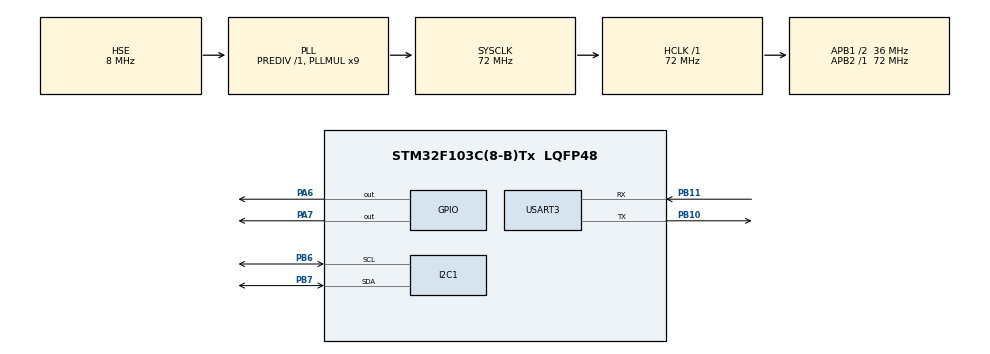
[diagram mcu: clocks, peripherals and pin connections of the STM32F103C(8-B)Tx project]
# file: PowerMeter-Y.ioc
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Dma.Request0=USART3_TX
Dma.Request1=USART3_RX
Dma.USART3_RX.1.Direction=DMA_PERIPH_TO_MEMORY
Dma.USART3_RX.1.Instance=DMA1_Channel3
Dma.USART3_RX.1.MemDataAlignment=DMA_MDATAALIGN_BYTE
Dma.USART3_RX.1.MemInc=DMA_MINC_ENABLE
Dma.USART3_RX.1.Mode=DMA_CIRCULAR
Dma.USART3_RX.1.PeriphDataAlignment=DMA_PDATAALIGN_BYTE
Dma.USART3_RX.1.PeriphInc=DMA_PINC_DISABLE
Dma.USART3_RX.1.Priority=DMA_PRIORITY_LOW
Dma.USART3_TX.0.Direction=DMA_MEMORY_TO_PERIPH
Dma.USART3_TX.0.Instance=DMA1_Channel2
Dma.USART3_TX.0.MemDataAlignment=DMA_MDATAALIGN_BYTE
Dma.USART3_TX.0.MemInc=DMA_MINC_ENABLE
Dma.USART3_TX.0.Mode=DMA_CIRCULAR
Dma.USART3_TX.0.PeriphDataAlignment=DMA_PDATAALIGN_BYTE
Dma.USART3_TX.0.PeriphInc=DMA_PINC_DISABLE
Dma.USART3_TX.0.Priority=DMA_PRIORITY_LOW
FREERTOS.Tasks01=Communicate,0,128,CommunicateTask,As weak,NULL,Dynamic,NULL,NULL
Mcu.Family=STM32F1
Mcu.Name=STM32F103C(8-B)Tx
Mcu.Package=LQFP48
NVIC.DMA1_Channel2_IRQn=true\:5\:0\:false\:false\:true\:true\:false\:true\:true
NVIC.DMA1_Channel3_IRQn=true\:5\:0\:false\:false\:true\:true\:false\:true\:true
NVIC.PriorityGroup=NVIC_PRIORITYGROUP_4
NVIC.TIM4_IRQn=true\:15\:0\:false\:false\:true\:false\:false\:true\:true
NVIC.TimeBase=TIM4_IRQn
NVIC.TimeBaseIP=TIM4
NVIC.USART3_IRQn=true\:5\:0\:false\:false\:true\:true\:true\:true\:true
PA13.Mode=Serial_Wire
PA13.Signal=SYS_JTMS-SWDIO
PA14.Mode=Serial_Wire
PA14.Signal=SYS_JTCK-SWCLK
PA6.GPIO_Speed=GPIO_SPEED_FREQ_HIGH
PA6.Signal=GPIO_Output
PA7.GPIO_Speed=GPIO_SPEED_FREQ_HIGH
PA7.Signal=GPIO_Output
PB10.Mode=Asynchronous
PB10.Signal=USART3_TX
PB11.Mode=Asynchronous
PB11.Signal=USART3_RX
PB6.Mode=I2C
PB6.Signal=I2C1_SCL
PB7.Mode=I2C
PB7.Signal=I2C1_SDA
PD0-OSC_IN.Mode=HSE-External-Oscillator
PD0-OSC_IN.Signal=RCC_OSC_IN
PD1-OSC_OUT.Mode=HSE-External-Oscillator
PD1-OSC_OUT.Signal=RCC_OSC_OUT
ProjectManager.HeapSize=0x200
ProjectManager.StackSize=0x400
ProjectManager.TargetToolchain=CMake
RCC.AHBFreq_Value=72000000
RCC.APB1CLKDivider=RCC_HCLK_DIV2
RCC.APB1Freq_Value=36000000
RCC.APB1TimFreq_Value=72000000
RCC.APB2Freq_Value=72000000
RCC.APB2TimFreq_Value=72000000
RCC.HCLKFreq_Value=72000000
RCC.PLLMUL=RCC_PLL_MUL9
RCC.PLLSourceVirtual=RCC_PLLSOURCE_HSE
RCC.SYSCLKFreq_VALUE=72000000
RCC.SYSCLKSource=RCC_SYSCLKSOURCE_PLLCLK
RCC.USBFreq_Value=72000000
USART3.VirtualMode=VM_ASYNC
VP_FREERTOS_VS_CMSIS_V1.Mode=CMSIS_V1
VP_SYS_VS_tim4.Mode=TIM4
board=custom

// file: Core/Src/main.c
/* USER CODE BEGIN Header */
/**
  ******************************************************************************
  * @file           : main.c
  * @brief          : Main program body
  ******************************************************************************
  * @attention
  *
  * Copyright (c) 2026 STMicroelectronics.
  * All rights reserved.
  *
  * This software is licensed under terms that can be found in the LICENSE file
  * in the root directory of this software component.
  * If no LICENSE file comes with this software, it is provided AS-IS.
  *
  ******************************************************************************
  */
/* USER CODE END Header */
#include "main.h"
#include "cmsis_os.h"
#include "dma.h"
#include "i2c.h"
#include "usart.h"
#include "gpio.h"

/* USER CODE BEGIN Includes */
#include "../../UserLib/INA226/INA226.h"
/* USER CODE END Includes */

/* USER CODE BEGIN PM */
uint8_t dma_flag = 1;
/* USER CODE END PM */

void SystemClock_Config(void);
void MX_FREERTOS_Init(void);

int main(void)
{

  /* MCU Configuration--------------------------------------------------------*/

  /* Reset of all peripherals, Initializes the Flash interface and the Systick. */
  HAL_Init();

  /* Configure the system clock */
  SystemClock_Config();

  /* Initialize all configured peripherals */
  MX_GPIO_Init();
  MX_DMA_Init();
  MX_I2C1_Init();
  MX_USART3_UART_Init();
  /* USER CODE BEGIN 2 */
  static float busvoltage;
  static float current;
  static float power;
  /* USER CODE END 2 */

  /* Call init function for freertos objects (in cmsis_os2.c) */
  MX_FREERTOS_Init();

  /* Start scheduler */
  osKernelStart();

  /* We should never get here as control is now taken by the scheduler */

  /* Infinite loop */
  /* USER CODE BEGIN WHILE */
  while (1)
  {
    if (Check() == 0) {
    busvoltage = BusVoltage();
      current = Current();
      power = Power();
    }
    HAL_Delay(50);
    /* USER CODE END WHILE */

  }
}

void SystemClock_Config(void)
{
  RCC_OscInitTypeDef RCC_OscInitStruct = {0};
  RCC_ClkInitTypeDef RCC_ClkInitStruct = {0};

  /** Initializes the RCC Oscillators according to the specified parameters
  * in the RCC_OscInitTypeDef structure.
  */
  RCC_OscInitStruct.OscillatorType = RCC_OSCILLATORTYPE_HSE;
  RCC_OscInitStruct.HSEState = RCC_HSE_ON;
  RCC_OscInitStruct.HSEPredivValue = RCC_HSE_PREDIV_DIV1;
  RCC_OscInitStruct.HSIState = RCC_HSI_ON;
  RCC_OscInitStruct.PLL.PLLState = RCC_PLL_ON;
  RCC_OscInitStruct.PLL.PLLSource = RCC_PLLSOURCE_HSE;
  RCC_OscInitStruct.PLL.PLLMUL = RCC_PLL_MUL9;
  if (HAL_RCC_OscConfig(&RCC_OscInitStruct) != HAL_OK)
  {
    Error_Handler();
  }

  /** Initializes the CPU, AHB and APB buses clocks
  */
  RCC_ClkInitStruct.ClockType = RCC_CLOCKTYPE_HCLK|RCC_CLOCKTYPE_SYSCLK
                              |RCC_CLOCKTYPE_PCLK1|RCC_CLOCKTYPE_PCLK2;
  RCC_ClkInitStruct.SYSCLKSource = RCC_SYSCLKSOURCE_PLLCLK;
  RCC_ClkInitStruct.AHBCLKDivider = RCC_SYSCLK_DIV1;
  RCC_ClkInitStruct.APB1CLKDivider = RCC_HCLK_DIV2;
  RCC_ClkInitStruct.APB2CLKDivider = RCC_HCLK_DIV1;

  if (HAL_RCC_ClockConfig(&RCC_ClkInitStruct, FLASH_LATENCY_2) != HAL_OK)
  {
    Error_Handler();
  }
}

void HAL_TIM_PeriodElapsedCallback(TIM_HandleTypeDef *htim)
{
  if (htim->Instance == TIM4)
  {
    HAL_IncTick();
  }
}

void Error_Handler(void)
{
  /* USER CODE BEGIN Error_Handler_Debug */
  /* UserLib can add his own implementation to report the HAL error return state */
  __disable_irq();
  while (1)
  {
  }
  /* USER CODE END Error_Handler_Debug */
}

#ifdef  USE_FULL_ASSERT
/**
  * @brief  Reports the name of the source file and the source line number
  *         where the assert_param error has occurred.
  * @param  file: pointer to the source file name
  * @param  line: assert_param error line source number
  * @retval None
  */
void assert_failed(uint8_t *file, uint32_t line)
{
  /* USER CODE BEGIN 6 */
  /* UserLib can add his own implementation to report the file name and line number,
     ex: printf("Wrong parameters value: file %s on line %d\r\n", file, line) */
  /* USER CODE END 6 */
}
#endif /* USE_FULL_ASSERT */

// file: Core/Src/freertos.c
/* USER CODE BEGIN Header */
/**
  ******************************************************************************
  * File Name          : freertos.c
  * Description        : Code for freertos applications
  ******************************************************************************
  * @attention
  *
  * Copyright (c) 2026 STMicroelectronics.
  * All rights reserved.
  *
  * This software is licensed under terms that can be found in the LICENSE file
  * in the root directory of this software component.
  * If no LICENSE file comes with this software, it is provided AS-IS.
  *
  ******************************************************************************
  */
/* USER CODE END Header */

#include "FreeRTOS.h"
#include "task.h"
#include "main.h"
#include "cmsis_os.h"

osThreadId CommunicateHandle;

void CommunicateTask(void const * argument);

void MX_FREERTOS_Init(void); /* (MISRA C 2004 rule 8.1) */

/* GetIdleTaskMemory prototype (linked to static allocation support) */
void vApplicationGetIdleTaskMemory( StaticTask_t **ppxIdleTaskTCBBuffer, StackType_t **ppxIdleTaskStackBuffer, uint32_t *pulIdleTaskStackSize );

/* USER CODE BEGIN GET_IDLE_TASK_MEMORY */
static StaticTask_t xIdleTaskTCBBuffer;
static StackType_t xIdleStack[configMINIMAL_STACK_SIZE];

void vApplicationGetIdleTaskMemory( StaticTask_t **ppxIdleTaskTCBBuffer, StackType_t **ppxIdleTaskStackBuffer, uint32_t *pulIdleTaskStackSize )
{
  *ppxIdleTaskTCBBuffer = &xIdleTaskTCBBuffer;
  *ppxIdleTaskStackBuffer = &xIdleStack[0];
  *pulIdleTaskStackSize = configMINIMAL_STACK_SIZE;
  /* place for user code */
}
/* USER CODE END GET_IDLE_TASK_MEMORY */

void MX_FREERTOS_Init(void) {

  /* Create the thread(s) */
  /* definition and creation of Communicate */
  osThreadDef(Communicate, CommunicateTask, osPriorityNormal, 0, 128);
  CommunicateHandle = osThreadCreate(osThread(Communicate), NULL);

}

__weak void CommunicateTask(void const * argument)
{
  for(;;)
  {
    osDelay(1);
  }
}
